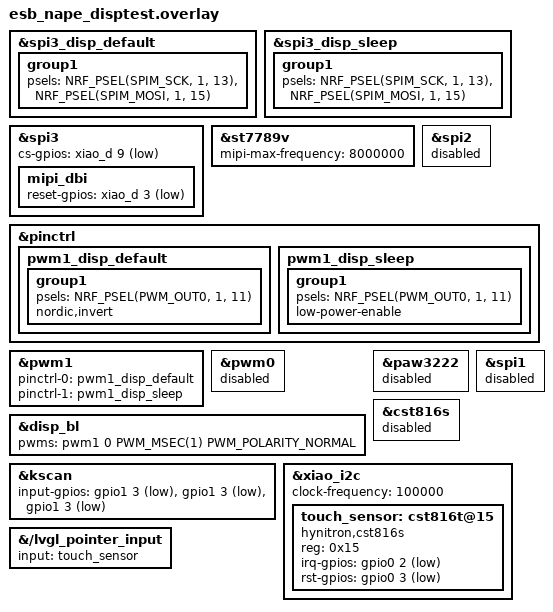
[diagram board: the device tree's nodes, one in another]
#include <zephyr/dt-bindings/gpio/gpio.h>
#include <zephyr/dt-bindings/pwm/pwm.h>

/*
 * Nape Deck DISPLAY TEST variant — layer on top of esb_nape_rx:
 *
 *   west build ... -DSHIELD="esb_nape_rx;esb_nape_disptest"
 *
 * The unit under test wires its ST7789V exactly like the Prospector
 * adapter (carrefinho/prospector-zmk-module, boards/seeeduino_xiao_ble
 * .overlay) instead of the pin plan in esb_nape_rx.overlay:
 *
 *   Display ST7789V, SPI3: SCK=D8(P1.13) MOSI=D10(P1.15)
 *                          CS=D9(P1.14)  DC=D7(P1.12, unchanged)
 *                          RESET=D3(P0.29)
 *                          BL=D6(P1.11), PWM1 ch0, inverted
 *
 * The display is wired Prospector-style (above). The PAW3222 sensor
 * — whose SPI1 pins (D8/D9/D10) collide with that display wiring —
 * is disabled outright below, together with its SPI1 bus (SPIM1
 * shares the 0x40004000 instance with TWIM1, so disabling it also
 * frees the peripheral for the touch bus).
 *
 * Touch (Step 2 production integration, moved here from
 * esb_nape_touchtest v4, which proved this recipe on this hardware —
 * it mirrors the user's prospector-bridge firmware): the CST816T
 * sits on &xiao_i2c, which in this Zephyr tree is i2c1 (board-default
 * pins SDA=P0.04 / SCL=P0.05 = XIAO D4/D5, exactly where the Scanner
 * harness lands TP_SDA/TP_SCL), at 100 kHz, in interrupt mode
 * (irq-gpios TP_IRQ -> D0 = P0.02, rst-gpios TP_RST -> D1 = P0.03;
 * see esb_nape_disptest.conf for CONFIG_INPUT_CST816S_INTERRUPT=y).
 * The old CST816S node esb_nape_rx puts on i2c0 is disabled and the
 * LVGL pointer input is repointed at the new node.
 *
 * Panel parameters (size, offsets, mdac, init values) are NOT touched
 * here; they remain whatever esb_nape_rx defines.
 */

/* ---- Display SPI3 pinctrl: SCK P0.03->P1.13, MOSI P0.29->P1.15 ---- */
&spi3_disp_default {
	group1 {
		psels = <NRF_PSEL(SPIM_SCK, 1, 13)>,
			<NRF_PSEL(SPIM_MOSI, 1, 15)>;
	};
};

&spi3_disp_sleep {
	group1 {
		psels = <NRF_PSEL(SPIM_SCK, 1, 13)>,
			<NRF_PSEL(SPIM_MOSI, 1, 15)>;
		/* low-power-enable stays from the esb_nape_rx definition. */
	};
};

/* ---- Display CS: D2(P0.28) -> D9(P1.14); panel reset on D3(P0.29).
 *      DC stays D7(P1.12) via the mipi_dbi node's dc-gpios. ---- */
&spi3 {
	cs-gpios = <&xiao_d 9 GPIO_ACTIVE_LOW>;

	mipi_dbi {
		/* In this Zephyr version the ST7789V driver resets the panel
		 * through the MIPI-DBI host (mipi_dbi_reset()), so reset-gpios
		 * belongs on the mipi_dbi node — in the flat Prospector
		 * overlay it sat on the panel node itself. */
		reset-gpios = <&xiao_d 3 GPIO_ACTIVE_LOW>;
	};
};

/* ---- Display SPI clock bisect: the panel lights but shows only
 *      static vertical-stripe garbage (the ST7789's uninitialized
 *      GRAM pattern), so init/frame writes are not landing cleanly.
 *      Drop the clock from the base shield's 30 MHz to 8 MHz to test
 *      whether the Scanner harness is the limit. ---- */
&st7789v {
	mipi-max-frequency = <8000000>;
};

/* ---- Disable the XIAO board's default SPI bus (spi2 / xiao_spi).
 *      The Zephyr xiao_ble board definition enables spi2 with pinctrl
 *      claiming SPIM_SCK=P1.13, SPIM_MOSI=P1.15, SPIM_MISO=P1.14 —
 *      exactly this build's display SCK/MOSI pins and the display CS
 *      pin (P1.14, a cs-gpios GPIO on spi3). Zephyr pinctrl has no
 *      arbitration between peripherals: spi2's init (or its pinctrl
 *      sleep state) rewires those pins to the idle SPIM2, so the panel
 *      never latches a single command and stays on its power-on GRAM
 *      garbage. The bus has no devices here; switch it off.
 *      (The onboard QSPI flash is NOT involved: qspi_default uses
 *      P0.20-P0.25.) ---- */
&spi2 {
	status = "disabled";
};

/* ---- Backlight: PWM0/P0.16 -> PWM1 ch0 on D6(P1.11), inverted.
 *      The pwm-leds node label (disp_bl) is unchanged, so the
 *      activity-linked dimming in esb_nape_rx/src/brightness.c keeps
 *      driving the same logical backlight. ---- */
&pinctrl {
	pwm1_disp_default: pwm1_disp_default {
		group1 {
			psels = <NRF_PSEL(PWM_OUT0, 1, 11)>;
			nordic,invert;
		};
	};

	pwm1_disp_sleep: pwm1_disp_sleep {
		group1 {
			psels = <NRF_PSEL(PWM_OUT0, 1, 11)>;
			low-power-enable;
		};
	};
};

&pwm1 {
	status = "okay";
	pinctrl-0 = <&pwm1_disp_default>;
	pinctrl-1 = <&pwm1_disp_sleep>;
	pinctrl-names = "default", "sleep";
};

/* P0.16 backlight PWM of the base shield is not wired on this unit. */
&pwm0 {
	status = "disabled";
};

&disp_bl {
	pwms = <&pwm1 0 PWM_MSEC(1) PWM_POLARITY_NORMAL>;
};

/* ---- Trackball PAW3222: DISABLED on this unit.
 *      The sensor is not connected, and its real pins (SPI1 SCK=D8,
 *      SDIO=D10, CS=D9, MOTION=D0) collide with the Prospector
 *      display wiring above. Disable the sensor and its bus
 *      outright (the touchtest v4 approach, proven on hardware):
 *      SPIM1 shares its peripheral instance with TWIM1, so this
 *      also frees instance 1 for the touch I2C bus below. ---- */
&paw3222 {
	status = "disabled";
};

&spi1 {
	status = "disabled";
};

/* ---- Local keys: PARKED.
 *      No physical keys are connected, so the base shield's kscan
 *      inputs (D4/D5/D6) float with pull-ups. D6 (P1.11) is worse:
 *      in this variant it is also the backlight PWM output, and
 *      key 3 is bound to &mkp MCLK — the contested, toggling line
 *      produced phantom middle clicks on the host. D4/D5 are now
 *      also the touch I2C lines. Park all three kscan inputs on a
 *      single GPIO that is not broken out on the XIAO and claimed
 *      by nothing else in this build, P1.03, so they can never
 *      generate key events (the touchtest v4 parking; the kscan
 *      node itself cannot be disabled — zmk's physical_layouts.c
 *      takes DEVICE_DT_GET(DT_CHOSEN(zmk_kscan)) unconditionally).
 *      The production esb_nape_rx keymap/kscan are untouched. ---- */
&kscan {
	input-gpios =
		<&gpio1 3 (GPIO_PULL_UP | GPIO_ACTIVE_LOW)>,
		<&gpio1 3 (GPIO_PULL_UP | GPIO_ACTIVE_LOW)>,
		<&gpio1 3 (GPIO_PULL_UP | GPIO_ACTIVE_LOW)>;
};

/* ---- The old touch node on i2c0 (esb_nape_rx) is replaced. ---- */
&cst816s {
	status = "disabled";
};

/* ---- Touch: CST816T on &xiao_i2c (i2c1), mirroring
 *      prospector-bridge config/xiao_ble.overlay. The bridge
 *      expresses the GPIOs via &xiao_d (D0/D1); the connector map
 *      resolves those to gpio0 2 / gpio0 3, which is what the rest
 *      of our overlays use directly. ---- */
&xiao_i2c {
	/* The board stack leaves i2c1 disabled (esb_nape_rx turns it
	 * off for the trackball SPIM1, and ZMK's xiao_ble turns unused
	 * peripherals off); the bridge build enables it by using the
	 * node. Without this the node has no device at all and the
	 * driver never binds. */
	status = "okay";
	clock-frequency = <100000>; /* I2C_BITRATE_STANDARD */

	touch_sensor: cst816t@15 {
		compatible = "hynitron,cst816s";
		reg = <0x15>;
		irq-gpios = <&gpio0 2 (GPIO_ACTIVE_LOW | GPIO_PULL_UP)>;
		rst-gpios = <&gpio0 3 GPIO_ACTIVE_LOW>;
		status = "okay";
	};
};

/* ---- LVGL pointer input follows the new node. ---- */
&{/lvgl_pointer_input} {
	input = <&touch_sensor>;
};
